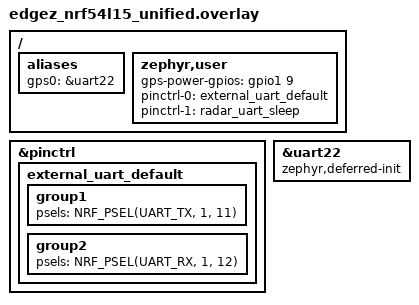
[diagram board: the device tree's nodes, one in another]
#include "edgez_nrf54l15_halow_camera.overlay"
/ {
 aliases { gps0 = &uart22; };
 zephyr,user {
  gps-power-gpios = <&gpio1 9 GPIO_ACTIVE_HIGH>;
  pinctrl-0 = <&external_uart_default>;
  pinctrl-1 = <&radar_uart_sleep>;
  pinctrl-names = "default", "sleep";
 };
};
&pinctrl {
 external_uart_default: external_uart_default {
  group1 { psels = <NRF_PSEL(UART_TX, 1, 11)>; };
  group2 { psels = <NRF_PSEL(UART_RX, 1, 12)>; };
 };
};
&uart22 { zephyr,deferred-init; };
